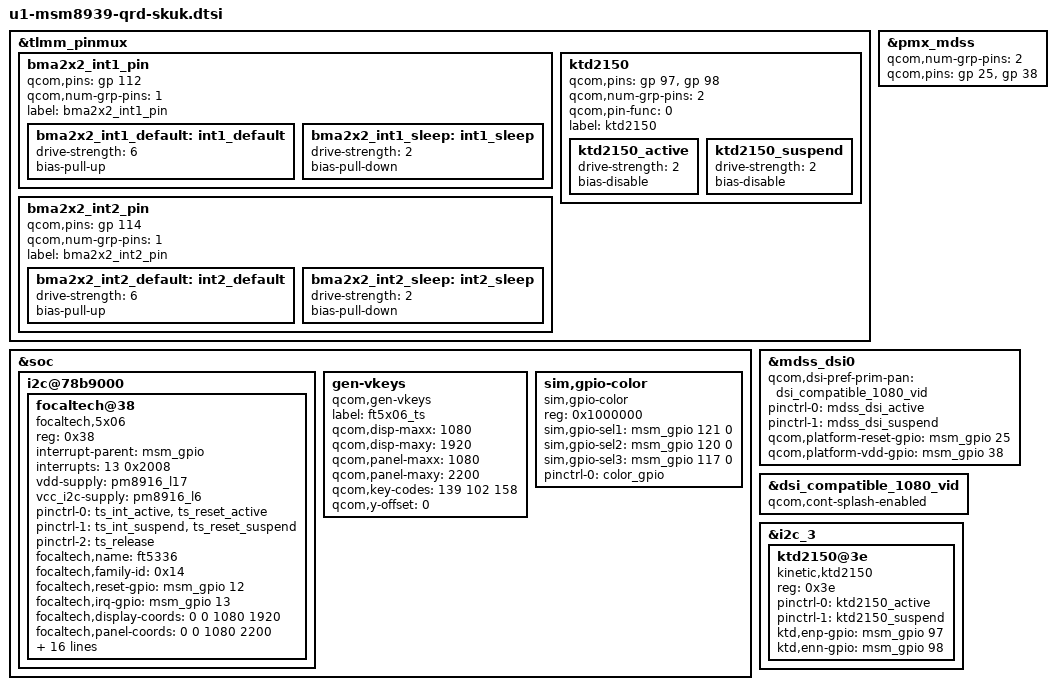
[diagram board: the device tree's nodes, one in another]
/* Copyright (c) 2014-2015, The Linux Foundation. All rights reserved.
 *
 * This program is free software; you can redistribute it and/or modify
 * it under the terms of the GNU General Public License version 2 and
 * only version 2 as published by the Free Software Foundation.
 *
 * This program is distributed in the hope that it will be useful,
 * but WITHOUT ANY WARRANTY; without even the implied warranty of
 * MERCHANTABILITY or FITNESS FOR A PARTICULAR PURPOSE.  See the
 * GNU General Public License for more details.
 */

#include "dsi-panel-compatible-1080p-video.dtsi"

&tlmm_pinmux {
	bma2x2_int1_pin {
		qcom,pins = <&gp 112>;
		qcom,num-grp-pins = <1>;
		label = "bma2x2_int1_pin";
		bma2x2_int1_default: int1_default {
			  drive-strength = <6>;
			  bias-pull-up;
		};
		bma2x2_int1_sleep: int1_sleep {
			  drive-strength = <2>;
			  bias-pull-down;
		};
	};

	bma2x2_int2_pin {
		qcom,pins = <&gp 114>;
		qcom,num-grp-pins = <1>;
		label = "bma2x2_int2_pin";
		bma2x2_int2_default: int2_default {
			  drive-strength = <6>;
			  bias-pull-up;
		};
		bma2x2_int2_sleep: int2_sleep {
			  drive-strength = <2>;
			  bias-pull-down;
		};
	};

	ktd2150 {
		qcom,pins = <&gp 97>, <&gp 98>;
		qcom,num-grp-pins = <2>;
		qcom,pin-func = <0>;
		label = "ktd2150";

		ktd2150_active: ktd2150_active {
			drive-strength = <2>; /* 2 MA */
			bias-disable;         /* No PULL */
		};

		ktd2150_suspend: ktd2150_suspend {
			drive-strength = <2>; /* 2 MA */
			bias-disable;	      /* No PULL */
		};
	};
};

&soc {
	i2c@78b9000 { /* BLSP1 QUP5 */
		focaltech@38 {
			compatible = "focaltech,5x06";
			reg = <0x38>;
			interrupt-parent = <&msm_gpio>;
			interrupts = <13 0x2008>;
			vdd-supply = <&pm8916_l17>;
			vcc_i2c-supply = <&pm8916_l6>;
			/* pins used by touchscreen */
			pinctrl-names = "pmx_ts_active","pmx_ts_suspend","pmx_ts_release";
			pinctrl-0 = <&ts_int_active &ts_reset_active>;
			pinctrl-1 = <&ts_int_suspend &ts_reset_suspend>;
			pinctrl-2 = <&ts_release>;
			focaltech,name = "ft5336";
			focaltech,family-id = <0x14>;
			focaltech,reset-gpio = <&msm_gpio 12 0x0>;
			focaltech,irq-gpio = <&msm_gpio 13 0x2008>;
			focaltech,display-coords = <0 0 1080 1920>;
			focaltech,panel-coords = <0 0 1080 2200>;
			focaltech,button-map= <139 102 158>;
			focaltech,no-force-update;
			focaltech,i2c-pull-up;
			focaltech,group-id = <1>;
			focaltech,hard-reset-delay-ms = <100>;
			focaltech,soft-reset-delay-ms = <200>;
			focaltech,num-max-touches = <10>;
			focaltech,fw-name = "ft_8926_qrd_fw.bin";
			focaltech,fw-delay-aa-ms = <30>;
			focaltech,fw-delay-55-ms = <30>;
			focaltech,fw-upgrade-id1 = <0x11>;
			focaltech,fw-upgrade-id2 = <0x11>;
			focaltech,fw-delay-readid-ms = <10>;
			focaltech,fw-delay-era-flsh-ms = <2000>;
			focaltech,fw-auto-cal;
			focaltech,ignore-id-check;
		};
	};

	gen-vkeys {
		compatible = "qcom,gen-vkeys";
		label = "ft5x06_ts";
		qcom,disp-maxx = <1080>;
		qcom,disp-maxy = <1920>;
		qcom,panel-maxx = <1080>;
		qcom,panel-maxy = <2200>;
		qcom,key-codes = <139 102 158>;
		qcom,y-offset = <0>;
	};

	sim,gpio-color{
                compatible = "sim,gpio-color";
		reg=<0x1000000>;
                sim,gpio-sel1 = <&msm_gpio 121 0>;
                sim,gpio-sel2 = <&msm_gpio 120 0>;
                sim,gpio-sel3 = <&msm_gpio 117 0>;

                pinctrl-names = "default";
                pinctrl-0 = <&color_gpio>;
        };
};

&pmx_mdss {
	qcom,num-grp-pins = <2>;
	qcom,pins = <&gp 25>,<&gp 38>;
};

&mdss_dsi0 {
	qcom,dsi-pref-prim-pan = <&dsi_compatible_1080_vid>;
	pinctrl-names = "mdss_default", "mdss_sleep";
	pinctrl-0 = <&mdss_dsi_active>;
	pinctrl-1 = <&mdss_dsi_suspend>;

	qcom,platform-reset-gpio = <&msm_gpio 25 0>;
	qcom,platform-vdd-gpio = <&msm_gpio 38 0>;
	//qcom,platform-bklight-en-gpio = <&msm_gpio 119 0>;
	//qcom,platform-vdd-gpio = <&msm_gpio 102 0>;
	//qcom,platform-avdd-gpio = <&msm_gpio 51 0>;
};

&dsi_compatible_1080_vid {
	qcom,cont-splash-enabled;
	/*qcom,esd-check-enabled;
	qcom,mdss-dsi-pan-enable-dynamic-fps;
	qcom,mdss-dsi-pan-fps-update = "dfps_immediate_porch_mode";*/
};

&i2c_3 {
	ktd2150@3e {
		compatible = "kinetic,ktd2150";
		reg = <0x3e>;
		pinctrl-names = "ktd2150_active","ktd2150_suspend";
		pinctrl-0 = <&ktd2150_active>;
		pinctrl-1 = <&ktd2150_suspend>;
		ktd,enp-gpio = <&msm_gpio 97 0>;
		ktd,enn-gpio = <&msm_gpio 98 0>;
	};

};
